# nrf7140_sysctrl register map
Vendor: Nordic Semiconductor; Series: nRF71; File version: 1
Registers are 32-bit, read-write, reset 0x0 unless marked. A register's access mark holds for its fields unless they carry their own. Offsets are from the block's base; [hi:lo] are bit positions; 'fields as' and 'values as' point back to an identical list.

## GLOBAL_TBM — Trace buffer monitor
Base 0xBF003000
0x00 TASKS_START wo — Start counter
  [0] TASKS_START
    1=Trigger task
0x04 TASKS_STOP wo — Stop counter, clear counter value
  [0] TASKS_STOP
    1=Trigger task
0x08 TASKS_FLUSH wo — Save current counter value to COUNTSNAPSHOT
  [0] TASKS_FLUSH
    1=Trigger task
0x100 EVENTS_HALFFULL — Counter value equals half-full
  [0] EVENTS_HALFFULL
    0=NotGenerated (Event not generated); 1=Generated (Event generated)
0x104 EVENTS_FULL — Counter value equals full
  [0] EVENTS_FULL
    values as EVENTS_HALFFULL.EVENTS_HALFFULL
0x108 EVENTS_FLUSH — Counter value saved to COUNTSNAPSHOT due to flush
  [0] EVENTS_FLUSH
    values as EVENTS_HALFFULL.EVENTS_HALFFULL
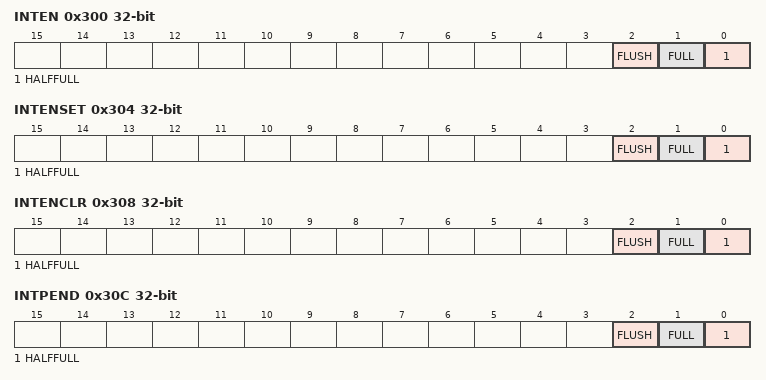
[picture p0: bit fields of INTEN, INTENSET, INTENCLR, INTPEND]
0x300 INTEN — Enable or disable interrupt
  [all] fields
    0=Disabled; 1=Enabled
  [2] FLUSH — Enable or disable interrupt for event FLUSH
  [1] FULL — Enable or disable interrupt for event FULL
  [0] HALFFULL — Enable or disable interrupt for event HALFFULL
0x304 INTENSET — Enable interrupt
  [all] fields
    on read: 0=Disabled (Read: Disabled); 1=Enabled (Read: Enabled) | on write: 1=Set (Enable)
  [2] FLUSH — Write '1' to enable interrupt for event FLUSH
  [1] FULL — Write '1' to enable interrupt for event FULL
  [0] HALFFULL — Write '1' to enable interrupt for event HALFFULL
0x308 INTENCLR — Disable interrupt
  [all] fields
    on read: 0=Disabled (Read: Disabled); 1=Enabled (Read: Enabled) | on write: 1=Clear (Disable)
  [2] FLUSH — Write '1' to disable interrupt for event FLUSH
  [1] FULL — Write '1' to disable interrupt for event FULL
  [0] HALFFULL — Write '1' to disable interrupt for event HALFFULL
0x30C INTPEND ro — Pending interrupts
  [all] fields
    on read: 0=NotPending (Read: Not pending); 1=Pending (Read: Pending)
  [2] FLUSH — Read pending status of interrupt for event FLUSH
  [1] FULL — Read pending status of interrupt for event FULL
  [0] HALFFULL — Read pending status of interrupt for event HALFFULL
0x400 BUFFERSIZE reset 0x400 — System RAM trace buffer total size in bytes
  [12:0] BUFFERSIZE — Must only be configured in STOP mode. Must be programmed to multiple of 16 bytes to make half-buffer size always 64 bit word aligned. Typical minimum BUFFERSIZE value 0x010 i.e. 16 bytes, typical maximum value 0x1000 i.e. 4096 bytes.
    0=Zero (0 bytes); 16=Min (16 bytes); 0x1000=Max (4096 bytes)
0x404 COUNT — Counter current value
  [12:0] COUNT — Counter current value. Only writable when counter is in stopped state. Writing when not in stopped state will generate a bus fault.
0x408 COUNTSNAPSHOT ro — Copy of the current COUNT value
  [12:0] COUNTSNAPSHOT — TASKS_FLUSH will copy the current COUNT value to this register.

## RAMC110 — RAM Controller 0
Base 0x5F083000
Same registers: RAMC111 0x5F084000, RAMC112 0x5F085000, RAMC120 0x5F8C3000, RAMC121 0x5F8C4000, GLOBAL_RAMC122 0x5F8DA000, GLOBAL_RAMC123 0x5F8DD000, RAMC130 0x5F903000, RAMC131 0x5F904000
0x500 WAITSTATES — Waitstates for read operations.
  [0] WAITSTATES — Number of waitstates for a read from the RAM.

## SHA3 — CRACEN
Base 0x5F088000
0x100 EVENTS_CRYPTOMASTER — Event indicating that interrupt triggered at Cryptomaster
  [0] EVENTS_CRYPTOMASTER
    0=NotGenerated (Event not generated); 1=Generated (Event generated)
0x300 INTEN — Enable or disable interrupt
  [0] CRYPTOMASTER — Enable or disable interrupt for event CRYPTOMASTER
    0=Disabled; 1=Enabled
0x304 INTENSET — Enable interrupt
  [0] CRYPTOMASTER — Write '1' to enable interrupt for event CRYPTOMASTER
    on read: 0=Disabled (Read: Disabled); 1=Enabled (Read: Enabled) | on write: 1=Set (Enable)
0x308 INTENCLR — Disable interrupt
  [0] CRYPTOMASTER — Write '1' to disable interrupt for event CRYPTOMASTER
    on read: 0=Disabled (Read: Disabled); 1=Enabled (Read: Enabled) | on write: 1=Clear (Disable)
0x30C INTPEND ro — Pending interrupts
  [0] CRYPTOMASTER — Read pending status of interrupt for event CRYPTOMASTER
    on read: 0=NotPending (Read: Not pending); 1=Pending (Read: Pending)
0x400 ENABLE — Enable CRACEN peripheral modules.
  [0] CRYPTOMASTER — Enable cryptomaster
    0=Disabled (Cryptomaster disabled.); 1=Enabled (Cryptomaster enabled.)
